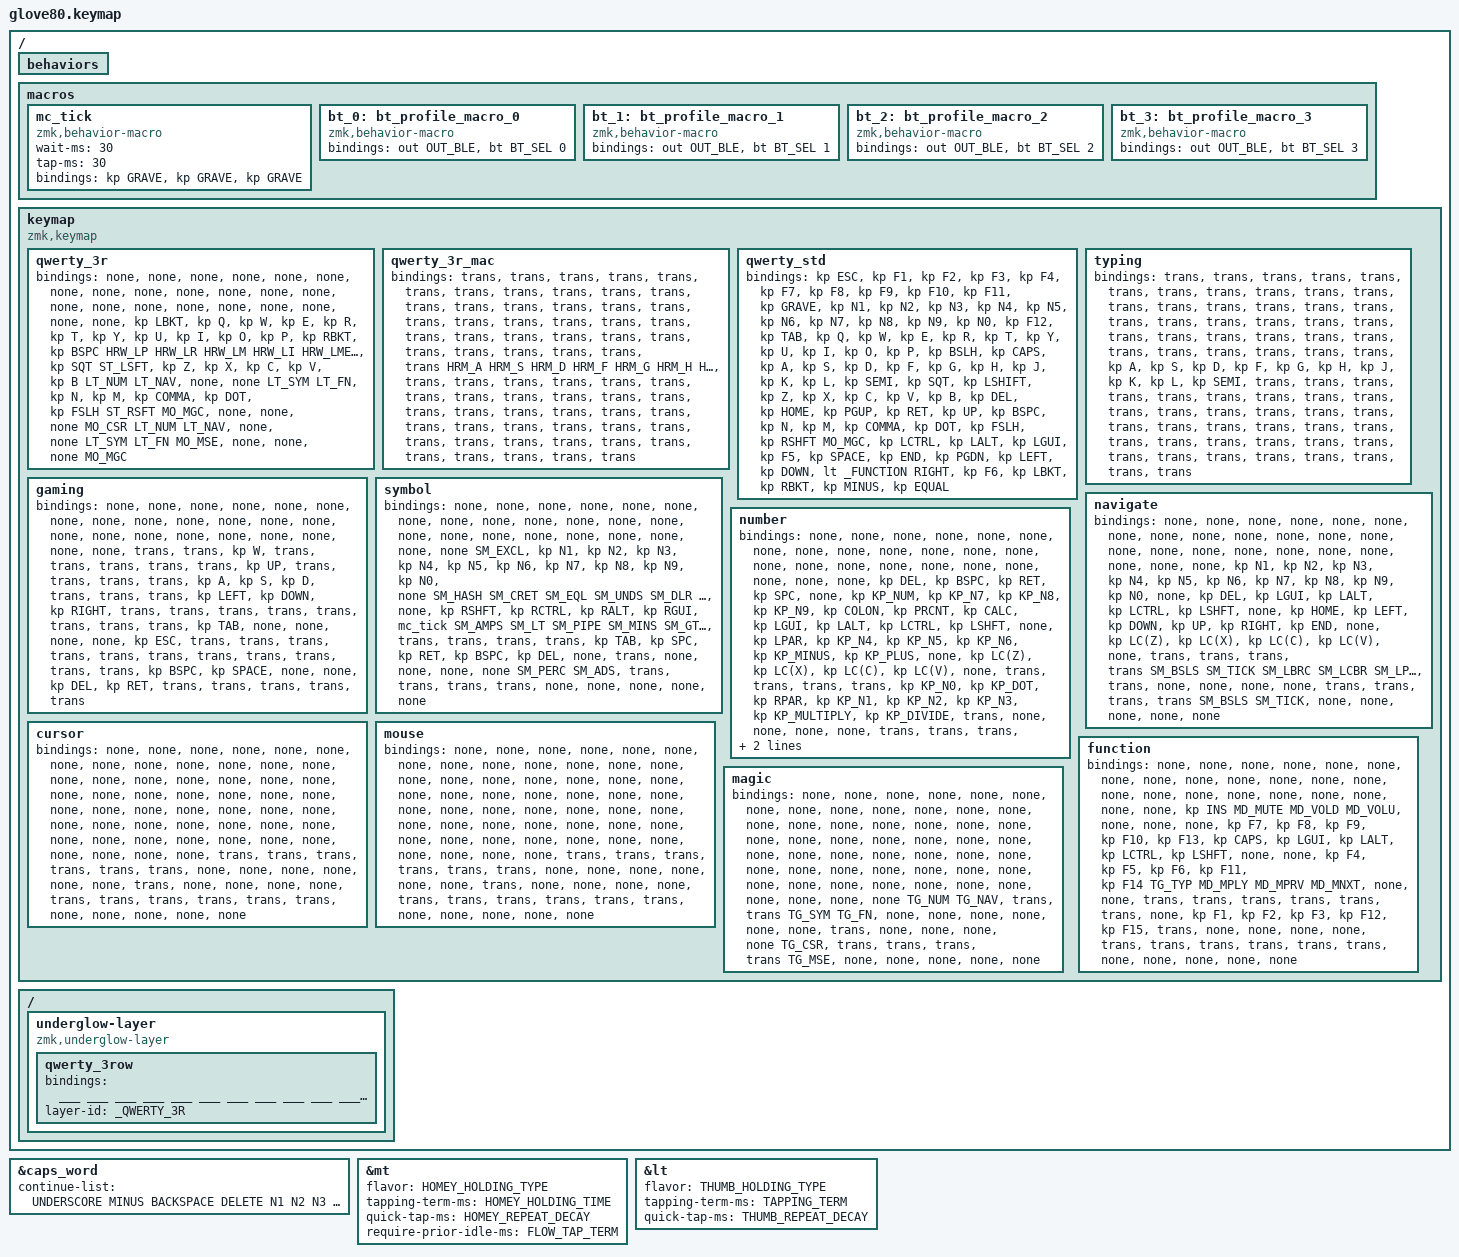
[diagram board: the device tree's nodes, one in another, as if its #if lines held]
/*
 * Copyright (c) 2020 The ZMK Contributors
 *
 * SPDX-License-Identifier: MIT
 */

#include <behaviors.dtsi>
#include <dt-bindings/zmk/keys.h>
#include <dt-bindings/zmk/bt.h>
#include <dt-bindings/zmk/ext_power.h>
#include <dt-bindings/zmk/outputs.h>
#include <dt-bindings/zmk/rgb.h>

// ###############################################################
// Define Aliases
// ###############################################################

// ---------------------------------------------------------------
// Define Aliases: Layers
// ---------------------------------------------------------------
// NOTE: These are just aliases for layer numbers. The actual layer numbers are determined by the order of the layers in the keymap.
// If you change the order of the layers, you must also change the layer numbers below.

/* #define DEFAULT           0   // Glove80 default layer */
/* #define LOWER             1   // Glove80 lower layer */
/* #define MAGIC             2   // Glove80 magic layer */
#define _QWERTY_3R         0   // TekBoArt Base QWERTY layer (3-row)
#define _QWERTY_3R_MAC     1   // TekBoArt Base QWERTY layer (3-row)
#define _QWERTY_STD        2   // TekBoArt Base Standard layer
#define _TYPING            3   // TekBoArt Typing layer
#define _GAMING            4   // TekBoArt Gaming layer
#define _SYMBOL            5   // TekBoArt Symbol layer
#define _NAVIGATE          6   // TekBoArt Symbol layer
#define _NUMBER            7   // TekBoArt Number layer
#define _CURSOR            8   // TekBoArt Cursor layer
#define _MOUSE             9   // TekBoArt Cursor layer
#define _FUNCTION          10   // TekBoArt Function layer
#define _MAGIC             11  // Tekboart magic layer

// ---------------------------------------------------------------
// Define Aliases: Layer Switch/Activtion
// ---------------------------------------------------------------
// (Base) QWERTY Layer (3-row)
#define TG_BASE  &tog _QWERTY_3R
#define TO_BASE  &to  _QWERTY_3R

// (Base) QWERTY Layer (3-row)
#define TG_BSMC  &tog _QWERTY_3R_MAC
#define TO_BSMC  &to  _QWERTY_3R_MAC

// (Base) QWERTY Layer (6-row)
#define TG_STD   &tog _QWERTY_STD
#define TO_STD   &to  _QWERTY_STD

// Typing Layer
#define TG_TYP   &tog _TYPING
#define TO_TYP   &to  _TYPING

// Gaming Layer
#define TG_GAME  &tog _GAMING
#define TO_GAME  &to  _GAMING

// --- Thumb Layer ---
// Symbol Layer
#define LT_SYM   &lt  _SYMBOL RET
#define MO_SYM   &mo  _SYMBOL
#define TG_SYM   &tog _SYMBOL
#define TO_SYM   &to  _SYMBOL

// Navigation Layer
#define LT_NAV   &lt  _NAVIGATE SPC
#define MO_NAV   &mo  _NAVIGATE
#define TG_NAV   &tog _NAVIGATE
#define TO_NAV   &to  _NAVIGATE

// Number Layer
#define LT_NUM   &lt  _NUMBER TAB
#define MO_NUM   &mo  _NUMBER
#define TG_NUM   &tog _NUMBER
#define TO_NUM   &to  _NUMBER

// Cursor Layer
#define LT_CSR   &lt  _CURSOR N1
#define MO_CSR   &mo  _CURSOR
#define TG_CSR   &tog _CURSOR
#define TO_CSR   &to  _CURSOR

// Mouse Layer
#define LT_MSE   &lt  _MOUSE N1
#define MO_MSE   &mo  _MOUSE
#define TG_MSE   &tog _MOUSE
#define TO_MSE   &to  _MOUSE

// Function Layer
#define LT_FN   &lt  _FUNCTION ESC
#define MO_FN   &mo  _FUNCTION
#define TG_FN   &tog _FUNCTION
#define TO_FN   &to  _FUNCTION

// Magic Layer
#define MO_MGC   &mo  _MAGIC
#define TG_MGC   &tog _MAGIC
#define TO_MGC   &to  _MAGIC

// ------- Define Aliases: Mod-Tap Keys  -------
#define MT_LSFT &mt LSHIFT LBKT
#define MT_RSFT &mt RSHIFT RBKT
#define MT_RALT &mt RALT TAB

// ------- Define Aliases: Sticky Keys  -------
// Sticky keys remain active until the next key is pressed.
// They are useful for one-handed typing, e.g., first letter capital.
// Sticky Mods (OSM)
#define ST_LSFT &sk LSHIFT
#define ST_RSFT &sk RSHIFT

// ------- Define Aliases: MEH keys  -------
/* #define MEH LC(LA(LS(A))) */

// ------- Define Aliases: Home Row Mods (HRMs) -------
// for Win/Linux
#define HRW_LP    &mt LGUI A
#define HRW_LR    &mt LALT S
#define HRW_LM    &mt LCTRL D
#define HRW_LI    &mt LSHFT F
#define HRW_LME    &kp G
#define HRW_RME    &kp H
#define HRW_RI    &mt RSHFT J
#define HRW_RM    &mt RCTRL K
#define HRW_RR    &mt RALT L
#define HRW_RP &mt RGUI SEMI
// for MAC
#define HRM_A    &mt LCTRL A
#define HRM_S    &mt LALT S
#define HRM_D    &mt LGUI D
#define HRM_F    &mt LSHFT F
#define HRM_G    &kp G
#define HRM_H    &kp H
#define HRM_J    &mt RSHFT J
#define HRM_K    &mt RGUI K
#define HRM_L    &mt RALT L
#define HRM_SCLN &mt RCTRL SEMI

// ------- Define Aliases: Symbols -------
#define SM_EXCL   &kp  EXCL // !
#define SM_ADS    &kp  AT // @
#define SM_HASH   &kp  HASH // #
#define SM_DLR    &kp  DLLR // $
#define SM_PERC   &kp  PRCNT // %
#define SM_CRET   &kp  CARET // ^
#define SM_AMPS   &kp  AMPS // &
#define SM_ASTR   &kp  ASTERISK // *
#define SM_LPRN   &kp  LPAR // (
#define SM_RPRN   &kp  RPAR // )
#define SM_LBRC   &kp  LBKT // [
#define SM_RBRC   &kp  RBKT // ]
#define SM_LCBR   &kp  LBRC // {
#define SM_RCBR   &kp  RBRC // }
#define SM_TICK   &kp  GRAVE // `
#define SM_TILD   &kp  TILDE // ~
#define SM_COMM   &kp  COMMA // ,
#define SM_LT     &kp  LT // <
#define SM_DOT    &kp  DOT // .
#define SM_GT     &kp  GT // >
#define SM_SLSH   &kp  FSLH // /
#define SM_QUES   &kp  QMARK // ?
#define SM_BSLS   &kp  BSLH // \ Backslash
#define SM_PIPE   &kp  PIPE // |
#define SM_COLN   &kp  COLON // :
#define SM_SCLN   &kp  SEMI // ;
#define SM_DQT    &kp  DQT // "
#define SM_QUOT   &kp  SQT // '
#define SM_EQL    &kp  EQUAL // =
#define SM_PLUS   &kp  PLUS // +
#define SM_MINS   &kp  MINUS // -
#define SM_UNDS   &kp  UNDER // _

// ------- Define Aliases: Media keys  -------
#define MD_MUTE &kp C_MUTE
#define MD_VOLU &kp C_VOL_UP
#define MD_VOLD &kp C_VOL_DN
#define MD_MPLY &kp C_PLAY_PAUSE
#define MD_MPRV &kp C_PREV
#define MD_MNXT &kp C_NEXT

// ------- Define Aliases: Misc keys  -------
#define CALC C_AL_CALC

// ---------------------------------------------------------------
// Define Aliases: OS specific actions
// ---------------------------------------------------------------
// Based on Sunsaku's: https://github.com/sunaku/glove80-keymaps
//
// OPERATING_SYSTEM defines which operating system you intend to use
// with this keymap, because shortcuts vary across operating systems.
//
// - https://zmk.dev/docs/codes
// - https://en.wikipedia.org/wiki/Table_of_keyboard_shortcuts
//
// This setting also affects the UNICODE() function defined below, as
// each OS has different shortcuts for typing Unicode hex characters.
//
// NOTE: You may need to enable Unicode hexadecimal input in your OS:
// - (macOS) https://uknowit.uwgb.edu/page.php?id=22623
//     and   https://github.com/ldanet/unicode-hex-input-fix
// - (Linux) https://help.ubuntu.com/stable/ubuntu-help/tips-specialchars.html.en#ctrlshiftu
// - (Windows) https://github.com/samhocevar/wincompose
//
// Specifically, Windows users should be running the WinCompose tool,
// which lets you type Unicode characters via hexadecimal codepoints.
//

// Define your preferred operating system
// TODO: can we detect the OS automatically? (like QMK does)
#ifndef OPERATING_SYSTEM
  #define OPERATING_SYSTEM 'L' // linux
//#define OPERATING_SYSTEM 'M' // macos
//#define OPERATING_SYSTEM 'W' // windows
#endif

// Aliases that are different for MacOS, but similr for Linux and Windows
#if OPERATING_SYSTEM == 'M'
  #define _C      LG
  #define _A_TAB  LGUI
  #define _G_TAB  LALT
  #define _REDO   LG(LS(Z))
  #define _POWER  K_POWER
  #define _WORD   LA
  #define _HOME   LG(LEFT)
  #define _END    LG(RIGHT)
  #define _EMOJI  LG(LC(SPACE))
  #define _FILES  LS(LA(M))
  #define _GLOBE  GLOBE
#else
  #define _C      LC
  #define _A_TAB  LALT
  #define _G_TAB  LGUI
  #define _REDO   LC(Y)
  #define _POWER  C_POWER
  #define _WORD   LC
  #define _HOME   HOME
  #define _END    END
  #define _EMOJI  LG(DOT)
  #define _FILES  LG(E)
  #define _GLOBE  LGUI
#endif
// Aliases shared across all OSes
#define _SLEEP      C_SLEEP

#if OPERATING_SYSTEM == 'W'
  #define _LOCK   LG(L)
#elif OPERATING_SYSTEM == 'M'
  #define _LOCK   _C(LC(Q))
#elif OPERATING_SYSTEM == 'L'
  #define _LOCK   K_LOCK
#endif
#define _UNDO       _C(Z)
#define _CUT        _C(X)
#define _COPY       _C(C)
#define _PASTE      _C(V)
#define _FIND       _C(F)
#define _FIND_NEXT  _C(G)
#define _FIND_PREV  _C(LS(G))

// ########################################################################
// Tap-Hold Configs
// ########################################################################

// ------------------------------------------------------------------------
// Set tapping TERMs
// ------------------------------------------------------------------------

// ........................................................................
// Guides
// ........................................................................

// Sunsaku's suggested TAPPING_TERM, based on difficulty:
// LEVEL 0 => sunaku (150ms)
// LEVEL 1 => novice (500ms)
// LEVEL 2 => slower (400ms)
// LEVEL 3 => normal (300ms)
// LEVEL 4 => faster (200ms)
// LEVEL 5 => expert (100ms)

// Tapping FLavors (flavor)
// hold_preferred:         (~QMK's HOLD_ON_OTHER_KEY_PRESS)(Good for Thumb keys)
// balanced:               (~QMK's PERMISSIVE_HOLD)
// tap-preferred:          (~QMK's default)(Good for Legato typing)
// tap-unless-interrupted:

// Quick Tap (quick_tap_ms): it's very useful for HRM keys that double as vim nav keys.

// require-prior-idle-ms: timeout for typing streak enforcement (~QMK's FLOW_TAP_TERM).

// ........................................................................
// migrated from QMK
// ........................................................................
#define TAPPING_TERM   150                   // The duration, after which, a key is considered held. Default: 200 (ms)
#define QUICK_TAP_TERM (TAPPING_TERM + 150)  // Time after a tap, during which holding the same key results in auto-repeat. Default: = TAPPING_TERM
#define FLOW_TAP_TERM  (TAPPING_TERM - 50)   // Disables holds when typing quickly.

// ........................................................................
// ZMK
// ........................................................................

// Home Row Mods (HRM)
#define HOMEY_HOLDING_TYPE "tap-preferred"             // Options: hold-preferred, balanced, tap-preferred
#define HOMEY_HOLDING_TIME (TAPPING_TERM + 90)         // HRM keys tapping TERM
#define HOMEY_STREAK_DECAY (TAPPING_TERM)              // Defines how long to wait until you can use HRM keys again.
#define HOMEY_REPEAT_DECAY (QUICK_TAP_TERM)  // Time after a tap, during which holding the same key results in auto-repeat.
// CHORD (i.e., opposite-hand)
#define CHORD_HOLDING_TYPE HOMEY_HOLDING_TYPE          // Defines the flavor of ZMK hold-tap flavor for CHORD keys
#define CHORD_HOLDING_TIME TAPPING_RESOLUTION
#define CHORD_STREAK_DECAY HOMEY_STREAK_DECAY
#define CHORD_REPEAT_DECAY HOMEY_REPEAT_DECAY
// INDEX Finger
#define INDEX_HOLDING_TYPE HOMEY_HOLDING_TYPE
#define INDEX_HOLDING_TIME (TAPPING_RESOLUTION + 30)
#define INDEX_STREAK_DECAY HOMEY_STREAK_DECAY
#define INDEX_REPEAT_DECAY HOMEY_REPEAT_DECAY
// MIDDLE Finger
#define MIDDY_HOLDING_TYPE HOMEY_HOLDING_TYPE
#define MIDDY_HOLDING_TIME (TAPPING_RESOLUTION + 60)
#define MIDDY_STREAK_DECAY HOMEY_STREAK_DECAY
#define MIDDY_REPEAT_DECAY HOMEY_REPEAT_DECAY
// RING Finger
#define RINGY_HOLDING_TYPE HOMEY_HOLDING_TYPE
#define RINGY_HOLDING_TIME (TAPPING_RESOLUTION + 90)
#define RINGY_STREAK_DECAY HOMEY_STREAK_DECAY
#define RINGY_REPEAT_DECAY HOMEY_REPEAT_DECAY
// PINKY Finger
#define PINKY_HOLDING_TYPE HOMEY_HOLDING_TYPE
#define PINKY_HOLDING_TIME (TAPPING_RESOLUTION + 120)
#define PINKY_STREAK_DECAY HOMEY_STREAK_DECAY
#define PINKY_REPEAT_DECAY HOMEY_REPEAT_DECAY
// THUMB_HOLDING_TYPE defines the flavor of ZMK hold-tap flavor for Thumb keys
#define THUMB_HOLDING_TYPE "hold-preferred"     // Options: hold-preferred, balanced (sunsaku's pref), tap-preferred
#define THUMB_HOLDING_TIME (TAPPING_TERM - 25)  // THUMB keys tapping TERM
#define THUMB_STREAK_DECAY TAPPING_TERM         // Defines how long to wait until you can use THUMB keys again.
#define THUMB_REPEAT_DECAY (QUICK_TAP_TERM)  // Time after a tap, during which holding the same key results in auto-repeat.

// ........................................................................
// Miryoku
// ........................................................................
#define ENFORCE_BILATERAL  // Cancels out single-handed HRMs activation and replacing them with taps.

// ########################################################################
// ZMK global overrides
// ########################################################################

// ------------------------------------------------------------------------
// CapsWord - ported from Pascal Getreuer's extension for QMK
// ------------------------------------------------------------------------

// - https://zmk.dev/docs/behaviors/caps-word
// - https://getreuer.info/posts/keyboards/caps-word/index.html
&caps_word {
  continue-list = <
    UNDERSCORE MINUS
    BACKSPACE DELETE
    N1 N2 N3 N4 N5 N6 N7 N8 N9 N0
    KP_N1 KP_N2 KP_N3 KP_N4 KP_N5 KP_N6 KP_N7 KP_N8 KP_N9 KP_N0
  >;
};

// TODO: enable caps_word with both shifts pressed

// ------------------------------------------------------------------------
// Default Mod-Tap keycode
// ------------------------------------------------------------------------
&mt {
    flavor = HOMEY_HOLDING_TYPE;
    tapping-term-ms = <HOMEY_HOLDING_TIME>;
    quick-tap-ms = <HOMEY_REPEAT_DECAY>;
    require-prior-idle-ms = <FLOW_TAP_TERM>;
};

// ------------------------------------------------------------------------
// Default Layer-Tap keycode
// ------------------------------------------------------------------------
&lt {
    flavor = THUMB_HOLDING_TYPE;
    tapping-term-ms = <TAPPING_TERM>;
    quick-tap-ms = <THUMB_REPEAT_DECAY>;
};

/ {
    // ########################################################################
    // Define Custom behaviors
    // ########################################################################
    behaviors {

        // TODO: Pressing magic key twice, will light up the assigned keys in magic key.
    };

    // ########################################################################
    // Macros
    // ########################################################################
    macros {
        // -------------------------------------------------------
        // Output three backticks (```) for code blocks in Markdown or other formats.
        // -------------------------------------------------------
        mc_tick: mc_tick {
            compatible = "zmk,behavior-macro";
            #binding-cells = <0>;
            wait-ms = <30>;
            tap-ms = <30>;
            bindings = <&kp GRAVE &kp GRAVE &kp GRAVE>;
        };

        // -------------------------------------------------------
        // Glove80 Bluetooth buttons
        // -------------------------------------------------------
        bt_0: bt_profile_macro_0 {
            compatible = "zmk,behavior-macro";
            #binding-cells = <0>;
            bindings
                = <&out OUT_BLE>,
                  <&bt BT_SEL 0>;
        };

        bt_1: bt_profile_macro_1 {
            compatible = "zmk,behavior-macro";
            #binding-cells = <0>;
            bindings
                = <&out OUT_BLE>,
                  <&bt BT_SEL 1>;
        };

        bt_2: bt_profile_macro_2 {
            compatible = "zmk,behavior-macro";
            #binding-cells = <0>;
            bindings
                = <&out OUT_BLE>,
                  <&bt BT_SEL 2>;
        };

        bt_3: bt_profile_macro_3 {
            compatible = "zmk,behavior-macro";
            #binding-cells = <0>;
            bindings
                = <&out OUT_BLE>,
                  <&bt BT_SEL 3>;
        };
    };

    // ########################################################################
    // Define Keymaps
    // ########################################################################
    keymap {
        compatible = "zmk,keymap";

        /* <layer_name> { */
        /*     bindings = < */
        /*     &none      &none    &none       &none       &none                                                                                                          &none      &none      &none      &none      &none */
        /*     &none      &none    &none       &none       &none       &none                                                                                   &none      &none      &none      &none      &none      &none */
        /*     &none      &none    &none       &none       &none       &none                                                                                   &none      &none      &none      &none      &none      &none */
        /*     &none      &none    &none       &none       &none       &none                                                                                   &none      &none      &none      &none      &none      &none */
        /*     &none      &none    &none       &none       &none       &none      &none      &none      &none      &none      &none      &none      &none      &none      &none      &none      &none      &none */
        /*     &none      &none    &none       &none       &none                  &none      &none      &none      &none      &none      &none */
        /*     >; */
        /* }; */

        /* default_layer { */
        /*     // --------------------------------------------------------------------------------------------------------------------------------- */
        /*     // |  F1   |  F2  |  F3  |  F4  |  F5  |                                                               |  F6   |  F7   |  F8  |  F9  |  F10 | */
        /*     // |  =    |   1  |   2  |   3  |   4  |  5   |                                                 |  6   |   7   |   8   |   9  |   0  |   -  | */
        /*     // |  TAB  |   Q  |   W  |   E  |   R  |  T   |                                                 |  Y   |   U   |   I   |   O  |   P  |   \  | */
        /*     // |  ESC  |   A  |   S  |   D  |   F  |  G   |                                                 |  H   |   J   |   K   |   L  |   ;  |   '  | */
        /*     // |   `   |   Z  |   X  |   C  |   V  |  B   | LSHFT | LCTRL | LOWER | | LGUI  | RCTRL | RSHFT |  N   |   M   |   ,   |   .  |   /  | PGUP | */
        /*     // | _MAGIC | HOME |  END | LEFT | RIGHT|      | BSPC  | DEL   | LALT  | | RALT  | RET   | SPACE |      |  UP   | DOWN  |   [  |   ]  | PGDN | */
        /*  */
        /*     bindings = < */
            /* &trans    &trans    &trans    &trans    &trans                                                                                    &trans    &trans    &trans    &trans    &trans */
            /* &trans    &trans    &trans    &trans    &trans    &trans                                                                &trans    &trans    &trans    &trans    &trans    &trans */
            /* &trans    &trans    &trans    &trans    &trans    &trans                                                                &trans    &trans    &trans    &trans    &trans    &trans */
            /* &trans    &trans    &trans    &trans    &trans    &trans                                                                &trans    &trans    &trans    &trans    &trans    &trans */
            /* &trans    &trans    &trans    &trans    &trans    &trans    &trans    &trans    &trans    &trans    &trans    &trans    &trans    &trans    &trans    &trans    &trans    &trans */
            /* &trans    &trans    &trans    &trans    &trans              &trans    &trans    &trans    &trans    &trans    &trans              &trans    &trans    &trans    &trans    &trans */
        /*     >; */
        /* }; */

        qwerty_3r {
            bindings = <
            &none     &none     &none     &none     &none                                                                                     &none     &none     &none     &none     &none
            &none     &none     &none     &none     &none     &none                                                                 &none     &none     &none     &none     &none     &none
            &kp LBKT  &kp Q     &kp W     &kp E     &kp R     &kp T                                                                 &kp Y     &kp U     &kp I     &kp O     &kp P     &kp RBKT
            &kp BSPC  HRW_LP     HRW_LR     HRW_LM     HRW_LI     HRW_LME                                                                 HRW_RME     HRW_RI     HRW_RM     HRW_RR     HRW_RP  &kp SQT
            ST_LSFT   &kp Z     &kp X     &kp C     &kp V     &kp B     LT_NUM    LT_NAV    &none     &none     LT_SYM    LT_FN     &kp N     &kp M     &kp COMMA &kp DOT   &kp FSLH  ST_RSFT
            MO_MGC    &none     &none     &none     MO_CSR              LT_NUM    LT_NAV    &none     &none     LT_SYM    LT_FN               MO_MSE    &none     &none     &none     MO_MGC
            >;
        };

        qwerty_3r_mac{
            bindings = <
            &trans    &trans    &trans    &trans    &trans                                                                                    &trans    &trans    &trans    &trans    &trans
            &trans    &trans    &trans    &trans    &trans    &trans                                                                &trans    &trans    &trans    &trans    &trans    &trans
            &trans    &trans    &trans    &trans    &trans    &trans                                                                &trans    &trans    &trans    &trans    &trans    &trans
            &trans    HRM_A     HRM_S     HRM_D     HRM_F     HRM_G                                                                 HRM_H     HRM_J     HRM_K     HRM_L     HRM_SCLN  &trans
            &trans    &trans    &trans    &trans    &trans    &trans    &trans    &trans    &trans    &trans    &trans    &trans    &trans    &trans    &trans    &trans    &trans    &trans
            &trans    &trans    &trans    &trans    &trans              &trans    &trans    &trans    &trans    &trans    &trans              &trans    &trans    &trans    &trans    &trans
            >;
        };

        qwerty_std {
            bindings = <
            &kp ESC    &kp F1    &kp F2      &kp F3      &kp F4                                                                                               &kp F7  &kp F8      &kp F9      &kp F10     &kp F11
            &kp GRAVE  &kp N1    &kp N2      &kp N3      &kp N4      &kp N5                                                                           &kp N6  &kp N7  &kp N8      &kp N9      &kp N0      &kp F12
            &kp TAB    &kp Q     &kp W       &kp E       &kp R       &kp T                                                                            &kp Y   &kp U   &kp I       &kp O       &kp P       &kp BSLH
            &kp CAPS   &kp A     &kp S       &kp D       &kp F       &kp G                                                                            &kp H   &kp J   &kp K       &kp L       &kp SEMI    &kp SQT
            &kp LSHIFT &kp Z     &kp X       &kp C       &kp V       &kp B   &kp DEL     &kp HOME   &kp PGUP  &kp RET   &kp UP    &kp BSPC            &kp N   &kp M   &kp COMMA   &kp DOT     &kp FSLH    &kp RSHFT
            MO_MGC     &kp LCTRL &kp LALT    &kp LGUI    &kp F5              &kp SPACE   &kp END    &kp PGDN  &kp LEFT  &kp DOWN  &lt _FUNCTION RIGHT         &kp F6  &kp LBKT    &kp RBKT    &kp MINUS   &kp EQUAL
            >;
        };

        typing {
            bindings = <
            &trans     &trans    &trans      &trans      &trans                                                                                             &trans  &trans      &trans      &trans      &trans
            &trans     &trans    &trans      &trans      &trans      &trans                                                                         &trans  &trans  &trans      &trans      &trans      &trans
            &trans     &trans    &trans      &trans      &trans      &trans                                                                         &trans  &trans  &trans      &trans      &trans      &trans
            &trans     &kp A     &kp S       &kp D       &kp F       &kp G                                                                          &kp H   &kp J   &kp K       &kp L       &kp SEMI    &trans
            &trans     &trans    &trans      &trans      &trans      &trans    &trans      &trans       &trans      &trans     &trans     &trans    &trans  &trans   &trans     &trans      &trans      &trans
            &trans     &trans    &trans      &trans      &trans                &trans      &trans       &trans      &trans     &trans     &trans            &trans   &trans     &trans      &trans      &trans
            >;
        };


        // TODO: Finalize gaming layer to match my QMK
        gaming {
            bindings = <
            &none     &none     &none     &none     &none                                                                                   &none    &none      &none       &none       &none
            &none     &none     &none     &none     &none     &none                                                                 &none   &none    &none      &none       &none       &none
            &trans    &trans    &kp W     &trans    &trans    &trans                                                                &trans  &trans   &kp UP     &trans      &trans      &trans
            &trans    &kp A     &kp S     &kp D     &trans    &trans                                                                &trans  &kp LEFT &kp DOWN   &kp RIGHT   &trans      &trans
            &trans    &trans    &trans    &trans    &trans    &trans    &kp TAB   &none     &none     &none     &none     &kp ESC   &trans  &trans   &trans     &trans      &trans      &trans
            &trans    &trans    &trans    &trans    &trans              &kp BSPC  &kp SPACE &none     &none     &kp DEL   &kp RET   &trans  &trans   &trans     &trans      &trans
            >;
        };

        // TODO: Add Macro for trip backticks MC_TICK
        symbol {
            bindings = <
            &none     &none     &none     &none     &none                                                                                     &none     &none     &none     &none     &none
            &none     &none     &none     &none     &none     &none                                                                 &none     &none     &none     &none     &none     &none
            SM_EXCL   &kp N1    &kp N2    &kp N3    &kp N4    &kp N5                                                                &kp N6    &kp N7    &kp N8    &kp N9    &kp N0    &none
            SM_HASH   SM_CRET   SM_EQL    SM_UNDS   SM_DLR    SM_ASTR                                                               &none     &kp RSHFT &kp RCTRL &kp RALT  &kp RGUI  &mc_tick
            SM_AMPS   SM_LT     SM_PIPE   SM_MINS   SM_GT     SM_PLUS   SM_PERC   SM_ADS    &trans    &trans    &trans    &trans    &kp TAB   &kp SPC   &kp RET   &kp BSPC  &kp DEL   &none
            &trans    &none     &none     &none     &none               SM_PERC   SM_ADS    &trans    &trans    &trans    &trans              &none     &none     &none     &none     &none
            >;
        };

        // TODO: Add UNDO
        // TODO: Add REDO
        // TODO: Add CUT
        // TODO: Add COPY
        // TODO: Add PASTE
        // TODO: add SEL_WRD
        // TODO: add SEL_LNE
        // TODO: add DEL_NORM
        navigate {
            bindings = <
            &none     &none     &none     &none     &none                                                                                     &none     &none     &none     &none     &none
            &none     &none     &none     &none     &none     &none                                                                 &none     &none     &none     &none     &none     &none
            &none     &kp N1    &kp N2    &kp N3    &kp N4    &kp N5                                                                &kp N6    &kp N7    &kp N8    &kp N9    &kp N0    &none
            &kp DEL   &kp LGUI  &kp LALT  &kp LCTRL &kp LSHFT &none                                                                 &kp HOME  &kp LEFT  &kp DOWN  &kp UP    &kp RIGHT &kp END
            &none     &kp LC(Z) &kp LC(X) &kp LC(C) &kp LC(V) &none     &trans    &trans    &trans    &trans    SM_BSLS   SM_TICK   SM_LBRC   SM_LCBR   SM_LPRN   SM_RPRN   SM_RCBR   SM_RBRC
            &trans    &none     &none     &none     &none               &trans    &trans    &trans    &trans    SM_BSLS   SM_TICK             &none     &none     &none     &none     &none
            >;
        };

        // TODO: Add UNDO
        // TODO: Add REDO
        // TODO: Add CUT
        // TODO: Add COPY
        // TODO: Add PASTE
        // TODO: add SEL_WRD
        // TODO: add SEL_LNE
        number {
            bindings = <
            &none     &none     &none     &none     &none                                                                                       &none     &none     &none     &none            &none
            &none     &none     &none     &none     &none     &none                                                                  &none      &none     &none     &none     &none            &none
            &none     &kp DEL   &kp BSPC  &kp RET   &kp SPC   &none                                                                  &kp KP_NUM &kp KP_N7 &kp KP_N8 &kp KP_N9 &kp COLON        &kp PRCNT
            &kp CALC  &kp LGUI  &kp LALT  &kp LCTRL &kp LSHFT &none                                                                  &kp LPAR   &kp KP_N4 &kp KP_N5 &kp KP_N6 &kp KP_MINUS     &kp KP_PLUS
            &none     &kp LC(Z) &kp LC(X) &kp LC(C) &kp LC(V) &none     &trans    &trans    &trans    &trans    &kp KP_N0 &kp KP_DOT &kp RPAR   &kp KP_N1 &kp KP_N2 &kp KP_N3 &kp KP_MULTIPLY  &kp KP_DIVIDE
            &trans    &none     &none     &none     &none               &trans    &trans    &trans    &trans    &kp KP_N0 &kp KP_DOT            &none     &none     &none     &none            &none
            >;
        };

        // TODO: Add UNDO
        // TODO: Add REDO
        // TODO: Add CUT
        // TODO: Add COPY
        // TODO: Add PASTE
        // TODO: add SEL_WRD
        // TODO: add SEL_LNE
        cursor {
            bindings = <
            &none     &none     &none     &none     &none                                                                                     &none     &none     &none     &none     &none
            &none     &none     &none     &none     &none     &none                                                                 &none     &none     &none     &none     &none     &none
            &none     &none     &none     &none     &none     &none                                                                 &none     &none     &none     &none     &none     &none
            &none     &none     &none     &none     &none     &none                                                                 &none     &none     &none     &none     &none     &none
            &none     &none     &none     &none     &none     &none     &trans    &trans    &trans    &trans    &trans    &trans    &none     &none     &none     &none     &none     &none
            &trans    &none     &none     &none     &none               &trans    &trans    &trans    &trans    &trans    &trans              &none     &none     &none     &none     &none
            >;
        };

        mouse {
            bindings = <
            &none     &none     &none     &none     &none                                                                                     &none     &none     &none     &none     &none
            &none     &none     &none     &none     &none     &none                                                                 &none     &none     &none     &none     &none     &none
            &none     &none     &none     &none     &none     &none                                                                 &none     &none     &none     &none     &none     &none
            &none     &none     &none     &none     &none     &none                                                                 &none     &none     &none     &none     &none     &none
            &none     &none     &none     &none     &none     &none     &trans    &trans    &trans    &trans    &trans    &trans    &none     &none     &none     &none     &none     &none
            &trans    &none     &none     &none     &none               &trans    &trans    &trans    &trans    &trans    &trans              &none     &none     &none     &none     &none
            >;
        };

        // TODO: Add UR_GPT
        // TODO: Add AP_TERM
        // TODO: Add AP_CHRM
        // TODO: Add AP_FFOX
        function {
            bindings = <
            &none     &none     &none     &none     &none                                                                                     &none     &none     &none     &none     &none
            &none     &none     &none     &none     &none     &none                                                                 &none     &none     &none     &none     &none     &none
            &kp INS   MD_MUTE   MD_VOLD   MD_VOLU   &none     &none                                                                 &none     &kp F7    &kp F8    &kp F9    &kp F10   &kp F13
            &kp CAPS  &kp LGUI  &kp LALT  &kp LCTRL &kp LSHFT &none                                                                 &none     &kp F4    &kp F5    &kp F6    &kp F11   &kp F14
            TG_TYP    MD_MPLY   MD_MPRV   MD_MNXT   &none     &none     &trans    &trans    &trans    &trans    &trans    &trans    &none     &kp F1    &kp F2    &kp F3    &kp F12   &kp F15
            &trans    &none     &none     &none     &none               &trans    &trans    &trans    &trans    &trans    &trans              &none     &none     &none     &none     &none
            >;
        };

        magic {
            bindings = <
            &none     &none     &none     &none     &none                                                                                     &none     &none     &none     &none     &none
            &none     &none     &none     &none     &none     &none                                                                 &none     &none     &none     &none     &none     &none
            &none     &none     &none     &none     &none     &none                                                                 &none     &none     &none     &none     &none     &none
            &none     &none     &none     &none     &none     &none                                                                 &none     &none     &none     &none     &none     &none
            &none     &none     &none     &none     &none     &none     TG_NUM    TG_NAV    &trans    &trans    TG_SYM    TG_FN     &none     &none     &none     &none     &none     &none
            &trans    &none     &none     &none     &none               TG_CSR    &trans    &trans    &trans    &trans    TG_MSE              &none     &none     &none     &none     &none
            >;
        };

    };

    // ########################################################################
    // Define RGB Layout
    // ########################################################################
    //////////////////////////////////////////////////////////////////////////////
    //
    // Per-key RGB indicators for layers & mods -- requires PR36 beta firmware:
    // override "EXPERIMENTAL_RGB_LAYER" to "y" in Advanced Configuration and
    // select "community.pr36.per-key-rgb" from the drop-down menu located at
    // Glove80 Layout Editor > Settings > Advanced Settings > Firmware Version
    //
    // - https://github.com/moergo-sc/zmk/pull/36
    // - https://github.com/moergo-sc/zmk/pull/30
    // - https://github.com/zmkfirmware/zmk/pull/2752
    // - https://dev.glove80.com/#/layout/user/c42ac32d-dc0d-4160-9ee3-fd0fc15f1725
    //
    //////////////////////////////////////////////////////////////////////////////

    #if __has_include(<dt-bindings/zmk/rgb_colors.h>)
      //
      // Color definitions with conflict guard to prevent
      // accidental redefinition of common abbreviations.
      //
      #if defined(RED) || defined(RED_RGB) || \
          defined(COR) || defined(COR_RGB) || \
          defined(ORN) || defined(ORN_RGB) || \
          defined(GDN) || defined(GDN_RGB) || \
          defined(GOL) || defined(GOL_RGB) || \
          defined(YLW) || defined(YLW_RGB) || \
          defined(CHU) || defined(CHU_RGB) || \
          defined(GRN) || defined(GRN_RGB) || \
          defined(SPG) || defined(SPG_RGB) || \
          defined(CYN) || defined(CYN_RGB) || \
          defined(AZU) || defined(AZU_RGB) || \
          defined(TEA) || defined(TEA_RGB) || \
          defined(TUR) || defined(TUR_RGB) || \
          defined(BLU) || defined(BLU_RGB) || \
          defined(PUR) || defined(PUR_RGB) || \
          defined(MAJ) || defined(MAJ_RGB) || \
          defined(PNK) || defined(PNK_RGB) || \
          defined(WHT) || defined(WHT_RGB) || \
          defined(BLK) || defined(BLK_RGB) || \
          defined(___) || \
          defined(DUG) || defined(DUG_RGB) || \
          defined(LAC) || defined(LAC_RGB) || \
          defined(BSL) || defined(BNL) || defined(BCL) || \
          defined(SSL) || defined(SNL) || defined(SCL) || \
          defined(FST) || defined(WRP) || defined(SLO)
      #error "Naming conflict: 3-letter color abbreviation already defined!"
      #endif

      //
      // color definitions from QMK
      // https://github.com/qmk/qmk_firmware/blob/master/quantum/color.h
      //
      #define RED_RGB 0xFF0000 // #FF0000 RED      => RED (red)
      #define COR_RGB 0xFF7C4D // #FF7C4D CORAL    => COR (coral)
      #define ORN_RGB 0xFF8000 // #FF8000 ORANGE   => ORN (ornj)
      #define GDN_RGB 0xD9A521 // #D9A521 GOLDNROD => GDN (gold'nrod)
      #define GOL_RGB 0xFFD900 // #FFD900 GOLD     => GOL (gold)
      #define YLW_RGB 0xFFFF00 // #FFFF00 YELLOW   => YLW (yellow)
      #define CHU_RGB 0x80FF00 // #80FF00 CHARTRSE => CHU (chartreuse)
      #define GRN_RGB 0x00FF00 // #00FF00 GREEN    => GRN (green)
      #define SPG_RGB 0x00FF80 // #00FF80 SPRINGRN => SPG (spring green)
      #define CYN_RGB 0x00FFFF // #00FFFF CYAN     => CYN (sigh-an)
      #define AZU_RGB 0x99F5FF // #99F5FF AZURE    => AZU (a-zur)
      #define TEA_RGB 0x008080 // #008080 TEAL     => TEA (teel)
      #define TUR_RGB 0x476E6A // #476E6A TURQUOIS => TUR (turquoise)
      #define BLU_RGB 0x0000FF // #0000FF BLUE     => BLU (bloo)
      #define PUR_RGB 0x7A00FF // #7A00FF PURPLE   => PUR (purp)
      #define MAJ_RGB 0xFF00FF // #FF00FF MAGENTA  => MAJ (mah-jenta)
      #define PNK_RGB 0xFF80BF // #FF80BF PINK     => PNK (pink)
      #define WHT_RGB 0xFFFFFF // #FFFFFF WHITE    => WHT (white)
      #define BLK_RGB 0x000000 // #000000 BLACK    => BLK (blak)

      //
      // color definitions from MoErgo
      // https://github.com/moergo-sc/zmk/blob/aca523dfce9b6447ffd19d833b791d44f1f286de/app/src/rgb_underglow.c#L259-L265
      //
      #define DUG_RGB 0x00ff68 // #00ff68 DULL_GRN => DUG (dull green)
      #define LAC_RGB 0x6b1fce // #6b1fce LILAC    => LAC (lilac)

      //
      // underglow for the colors above
      //
      #define RED &ug RED_RGB
      #define COR &ug COR_RGB
      #define ORN &ug ORN_RGB
      #define GDN &ug GDN_RGB
      #define GOL &ug GOL_RGB
      #define YLW &ug YLW_RGB
      #define CHU &ug CHU_RGB
      #define GRN &ug GRN_RGB
      #define SPG &ug SPG_RGB
      #define CYN &ug CYN_RGB
      #define TUR &ug TUR_RGB
      #define BLU &ug BLU_RGB
      #define PUR &ug PUR_RGB
      #define MAJ &ug MAJ_RGB
      #define PNK &ug PNK_RGB
      #define WHT &ug WHT_RGB
      #define BLK &ug BLK_RGB
      #define ___ &ug BLK_RGB
      #define DUG &ug DUG_RGB
      #define LAC &ug LAC_RGB

      //
      // underglow for keyboard locks on the Base layer
      //
      #define BSL &ug_sl LAC_RGB WHT_RGB // ScrollLock COLOR_OFF COLOR_ON
      #define BNL &ug_nl LAC_RGB WHT_RGB // NumLock    COLOR_OFF COLOR_ON
      #define BCL &ug_cl BLK_RGB WHT_RGB // CapsLock   COLOR_OFF COLOR_ON

      //
      // underglow for keyboard locks on the System layer
      //
      #define SSL &ug_sl BLK_RGB WHT_RGB // ScrollLock COLOR_OFF COLOR_ON
      #define SNL &ug_nl BLK_RGB WHT_RGB // NumLock    COLOR_OFF COLOR_ON
      #define SCL &ug_cl BLK_RGB WHT_RGB // CapsLock   COLOR_OFF COLOR_ON

      //
      // colors for mouse speed scaling in Mouse layers
      //
      #define FST GOL
      #define SLO PNK
      #define WRP CHU

      // ==== PER-KEY-RGB <section begins> ====
      / {
        underglow-layer {
          compatible  = "zmk,underglow-layer";

          /*
          Template {
            bindings = <
              ___ ___ ___ ___ ___                                             ___ ___ ___ ___ ___
              ___ ___ ___ ___ ___ ___                                     ___ ___ ___ ___ ___ ___
              ___ ___ ___ ___ ___ ___                                     ___ ___ ___ ___ ___ ___
              ___ ___ ___ ___ ___ ___                                     ___ ___ ___ ___ ___ ___
              ___ ___ ___ ___ ___ ___     ___ ___ ___     ___ ___ ___     ___ ___ ___ ___ ___ ___
              ___ ___ ___ ___ ___         ___ ___ ___     ___ ___ ___         ___ ___ ___ ___ ___
            >;
            layer-id = <LAYER_Template>;
          };
          */

          // _QWERTY_3R
          /* #ifdef _QWERTY_3R */
          qwerty_3row {
            bindings = <
              ___ ___ ___ ___ ___                                             ___ ___ ___ ___ ___
              ___ ___ ___ ___ ___ ___                                     ___ ___ ___ ___ ___ ___
              ___ ___ ___ ___ ___ ___                                     ___ ___ ___ ___ ___ ___
              BCL RED RED RED RED ___                                     ___ RED RED RED RED ___
              ___ ___ ___ ___ ___ ___     ___ ___ ___     ___ ___ ___     ___ ___ ___ ___ ___ ___
              ___ ___ ___ ___ ___         ___ ___ ___     ___ ___ ___         ___ ___ ___ ___ ___
            >;
            layer-id = <_QWERTY_3R>;
          };
          /* #endif */

          // _QWERTY_STD
          // _TYPING
          // _GAMING
          // _SYMBOL
          // _NUMBER
          // _CURSOR
          // LOWER
          // _MAGIC
          // _FUNCTION

        };
      };
      // ==== PER-KEY-RGB <section ends> =====

      #undef RED
      #undef RED_RGB
      #undef COR
      #undef COR_RGB
      #undef ORN
      #undef ORN_RGB
      #undef GDN
      #undef GDN_RGB
      #undef GOL
      #undef GOL_RGB
      #undef YLW
      #undef YLW_RGB
      #undef CHU
      #undef CHU_RGB
      #undef GRN
      #undef GRN_RGB
      #undef SPG
      #undef SPG_RGB
      #undef CYN
      #undef CYN_RGB
      #undef AZU
      #undef AZU_RGB
      #undef TEA
      #undef TEA_RGB
      #undef TUR
      #undef TUR_RGB
      #undef BLU
      #undef BLU_RGB
      #undef PUR
      #undef PUR_RGB
      #undef MAJ
      #undef MAJ_RGB
      #undef PNK
      #undef PNK_RGB
      #undef WHT
      #undef WHT_RGB
      #undef BLK
      #undef BLK_RGB
      #undef ___
      #undef DUG
      #undef DUG_RGB
      #undef LAC
      #undef LAC_RGB

      #undef BSL
      #undef BNL
      #undef BCL

      #undef SSL
      #undef SNL
      #undef SCL

      #undef FST
      #undef WRP
      #undef SLO
    #endif

};
